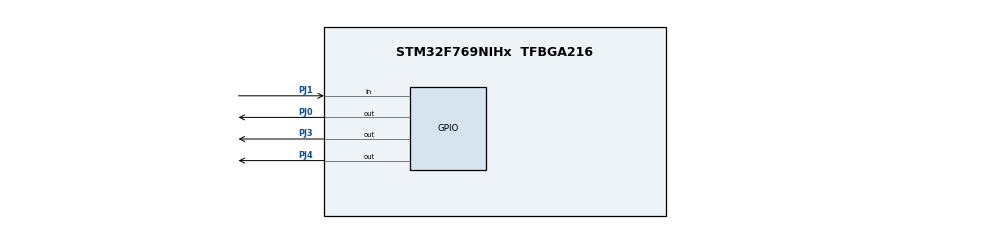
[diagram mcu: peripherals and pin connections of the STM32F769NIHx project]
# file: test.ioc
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Mcu.Family=STM32F7
Mcu.Name=STM32F769NIHx
Mcu.Package=TFBGA216
NVIC.PriorityGroup=NVIC_PRIORITYGROUP_4
NVIC.TIM3_IRQn=true\:0\:0\:false\:false\:true\:true\:true
PJ0.Signal=GPIO_Output
PJ1.Signal=GPIO_Input
PJ3.Signal=GPIO_Output
PJ4.Signal=GPIO_Output
ProjectManager.HeapSize=0x200
ProjectManager.StackSize=0x400
ProjectManager.TargetToolchain=STM32CubeIDE
RCC.HSE_VALUE=25000000
RCC.HSI_VALUE=16000000
RCC.LSE_VALUE=32768
RCC.USBFreq_Value=96000000
RCC.VCOOutputFreq_Value=192000000
TIM3.Period=499
TIM3.Prescaler=48000
VP_TIM3_VS_ClockSourceINT.Mode=Internal
board=custom

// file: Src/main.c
/* USER CODE BEGIN Header */
/**
  ******************************************************************************
  * @file           : main.c
  * @brief          : Main program body
  ******************************************************************************
  * @attention
  *
  * <h2><center>&copy; Copyright (c) 2019 STMicroelectronics.
  * All rights reserved.</center></h2>
  *
  * This software component is licensed by ST under BSD 3-Clause license,
  * the "License"; You may not use this file except in compliance with the
  * License. You may obtain a copy of the License at:
  *                        opensource.org/licenses/BSD-3-Clause
  *
  ******************************************************************************
  */
/* USER CODE END Header */

#include "main.h"

TIM_HandleTypeDef htim3;

void SystemClock_Config(void);
static void MX_GPIO_Init(void);
static void MX_TIM3_Init(void);
/* USER CODE BEGIN PFP */
int button_pressed=0;
int oldstate=0;
/* USER CODE END PFP */

/*static void debounce(void)
{
	//counter pentru stari egale
	static int count=0;
	//starea curenta
	static int button_state=0;

	//verificare buton
	int current_state=(GPIOJ->IDR & GPIO_PIN_1) == 1;

	if(current_state!=button_state)
	{
		count++;
		if(count>=4)
		{
			//4 verificari=>schimba starea
			button_state=current_state;
			//daca a fost apasat si nu eliberat
			if(current_state!=0)
				button_pressed=1;

			count=0;

		}
	}
	else
	{
		count=0;
	}

}*/

int main(void)
{

  /* MCU Configuration--------------------------------------------------------*/

  /* Reset of all peripherals, Initializes the Flash interface and the Systick. */
  HAL_Init();

  /* Configure the system clock */
  SystemClock_Config();

  /* Initialize all configured peripherals */
  MX_GPIO_Init();
  MX_TIM3_Init();
  /* USER CODE BEGIN 2 */
   HAL_TIM_Base_Start_IT(&htim3);
   int count=0;
  /* USER CODE END 2 */

  /* Infinite loop */
  while (1)
  {
	  HAL_Delay(60);

	 /* debounce();
	  if(button_pressed){
		  count=(count+1)%3;
	  }*/
	  if(HAL_GPIO_ReadPin(GPIOJ, GPIO_PIN_1)==GPIO_PIN_SET && oldstate !=HAL_GPIO_ReadPin(GPIOJ, GPIO_PIN_1)){
		  HAL_GPIO_WritePin(GPIOJ, GPIO_PIN_4,GPIO_PIN_RESET);
		           HAL_GPIO_WritePin(GPIOJ,GPIO_PIN_3,GPIO_PIN_RESET);
		           HAL_GPIO_WritePin(GPIOJ,GPIO_PIN_0,GPIO_PIN_RESET);
		           count=(count+1)%3;
	   }
		  switch(count)
		  {
		  case 0:
			     HAL_GPIO_WritePin(GPIOJ, GPIO_PIN_4,GPIO_PIN_SET);
		  	  	  break;
		  case 1:
			     HAL_GPIO_WritePin(GPIOJ,GPIO_PIN_3,GPIO_PIN_SET);

		  	          break;
		  case 2:
 	             HAL_GPIO_WritePin(GPIOJ,GPIO_PIN_0,GPIO_PIN_SET);

		  	          break;
		  }
         oldstate=HAL_GPIO_ReadPin(GPIOJ, GPIO_PIN_1);

  }
}

void SystemClock_Config(void)
{
  RCC_OscInitTypeDef RCC_OscInitStruct = {0};
  RCC_ClkInitTypeDef RCC_ClkInitStruct = {0};

  /** Configure the main internal regulator output voltage
  */
  __HAL_RCC_PWR_CLK_ENABLE();
  __HAL_PWR_VOLTAGESCALING_CONFIG(PWR_REGULATOR_VOLTAGE_SCALE3);
  /** Initializes the CPU, AHB and APB busses clocks
  */
  RCC_OscInitStruct.OscillatorType = RCC_OSCILLATORTYPE_HSI;
  RCC_OscInitStruct.HSIState = RCC_HSI_ON;
  RCC_OscInitStruct.HSICalibrationValue = RCC_HSICALIBRATION_DEFAULT;
  RCC_OscInitStruct.PLL.PLLState = RCC_PLL_NONE;
  if (HAL_RCC_OscConfig(&RCC_OscInitStruct) != HAL_OK)
  {
    Error_Handler();
  }
  /** Initializes the CPU, AHB and APB busses clocks
  */
  RCC_ClkInitStruct.ClockType = RCC_CLOCKTYPE_HCLK|RCC_CLOCKTYPE_SYSCLK
                              |RCC_CLOCKTYPE_PCLK1|RCC_CLOCKTYPE_PCLK2;
  RCC_ClkInitStruct.SYSCLKSource = RCC_SYSCLKSOURCE_HSI;
  RCC_ClkInitStruct.AHBCLKDivider = RCC_SYSCLK_DIV1;
  RCC_ClkInitStruct.APB1CLKDivider = RCC_HCLK_DIV1;
  RCC_ClkInitStruct.APB2CLKDivider = RCC_HCLK_DIV1;

  if (HAL_RCC_ClockConfig(&RCC_ClkInitStruct, FLASH_LATENCY_0) != HAL_OK)
  {
    Error_Handler();
  }
}

static void MX_TIM3_Init(void)
{

  TIM_ClockConfigTypeDef sClockSourceConfig = {0};
  TIM_MasterConfigTypeDef sMasterConfig = {0};

  htim3.Instance = TIM3;
  htim3.Init.Prescaler = 48000;
  htim3.Init.CounterMode = TIM_COUNTERMODE_UP;
  htim3.Init.Period = 499;
  htim3.Init.ClockDivision = TIM_CLOCKDIVISION_DIV1;
  htim3.Init.AutoReloadPreload = TIM_AUTORELOAD_PRELOAD_DISABLE;
  if (HAL_TIM_Base_Init(&htim3) != HAL_OK)
  {
    Error_Handler();
  }
  sClockSourceConfig.ClockSource = TIM_CLOCKSOURCE_INTERNAL;
  if (HAL_TIM_ConfigClockSource(&htim3, &sClockSourceConfig) != HAL_OK)
  {
    Error_Handler();
  }
  sMasterConfig.MasterOutputTrigger = TIM_TRGO_RESET;
  sMasterConfig.MasterSlaveMode = TIM_MASTERSLAVEMODE_DISABLE;
  if (HAL_TIMEx_MasterConfigSynchronization(&htim3, &sMasterConfig) != HAL_OK)
  {
    Error_Handler();
  }

}

static void MX_GPIO_Init(void)
{
  GPIO_InitTypeDef GPIO_InitStruct = {0};

  /* GPIO Ports Clock Enable */
  __HAL_RCC_GPIOJ_CLK_ENABLE();

  /*Configure GPIO pin Output Level */
  HAL_GPIO_WritePin(GPIOJ, GPIO_PIN_4|GPIO_PIN_3|GPIO_PIN_0, GPIO_PIN_RESET);

  /*Configure GPIO pins : PJ4 PJ3 PJ0 */
  GPIO_InitStruct.Pin = GPIO_PIN_4|GPIO_PIN_3|GPIO_PIN_0;
  GPIO_InitStruct.Mode = GPIO_MODE_OUTPUT_PP;
  GPIO_InitStruct.Pull = GPIO_NOPULL;
  GPIO_InitStruct.Speed = GPIO_SPEED_FREQ_LOW;
  HAL_GPIO_Init(GPIOJ, &GPIO_InitStruct);

  /*Configure GPIO pin : PJ1 */
  GPIO_InitStruct.Pin = GPIO_PIN_1;
  GPIO_InitStruct.Mode = GPIO_MODE_INPUT;
  GPIO_InitStruct.Pull = GPIO_NOPULL;
  HAL_GPIO_Init(GPIOJ, &GPIO_InitStruct);

}

void Error_Handler(void)
{
}

/************************ (C) COPYRIGHT STMicroelectronics *****END OF FILE****/
